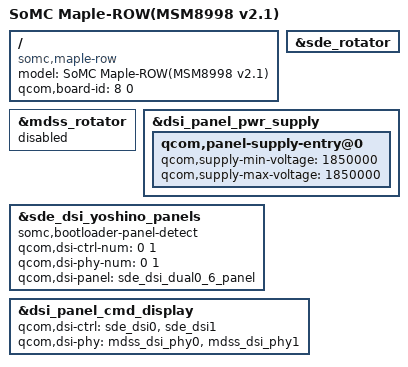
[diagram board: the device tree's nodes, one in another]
/* Copyright (c) 2016, The Linux Foundation. All rights reserved.
 *
 * This program is free software; you can redistribute it and/or modify
 * it under the terms of the GNU General Public License version 2 and
 * only version 2 as published by the Free Software Foundation.
 *
 * This program is distributed in the hope that it will be useful,
 * but WITHOUT ANY WARRANTY; without even the implied warranty of
 * MERCHANTABILITY or FITNESS FOR A PARTICULAR PURPOSE.  See the
 * GNU General Public License for more details.
 */
/*
 * Copyright (C) 2016 Sony Mobile Communications Inc.
 *
 * This program is free software; you can redistribute it and/or modify
 * it under the terms of the GNU General Public License version 2, as
 * published by the Free Software Foundation.
 */


/dts-v1/;

#include "msm8998-v2.1.dtsi"
#include "msm8998-sde.dtsi"
#include "msm8998-sde-display.dtsi"
#include "msm8998-mtp.dtsi"
#include "msm8998-yoshino-common.dtsi"
#include "msm8998-yoshino-common-sde-overlay.dtsi"
#include "msm8998-yoshino-maple_common.dtsi"
#include "dsi-panel-somc-maple-sde.dtsi"

/ {
	model = "SoMC Maple-ROW(MSM8998 v2.1)";
	compatible = "somc,maple-row", "qcom,msm8998";
	qcom,board-id = <8 0>;
};

/* Disable MDSS rotator node to use SDE rotator. */
&mdss_rotator {
	status = "disabled";
};

&sde_rotator {
	status = "ok";
};

&dsi_panel_pwr_supply {
	qcom,panel-supply-entry@0 {
		qcom,supply-min-voltage = <1850000>;
		qcom,supply-max-voltage = <1850000>;
	};
};

&sde_dsi_yoshino_panels {
	/* Only one possible panel on PROD SoMC Maple */
	somc,bootloader-panel-detect;

	/* Dual DSI single panel, clocked from MUX 0 */
	qcom,dsi-ctrl-num = <0 1>;
	qcom,dsi-phy-num = <0 1>;

	qcom,dsi-panel = <&sde_dsi_dual0_6_panel>;
};

&dsi_panel_cmd_display {
	qcom,dsi-ctrl = <&sde_dsi0 &sde_dsi1>;
	qcom,dsi-phy = <&mdss_dsi_phy0 &mdss_dsi_phy1>;
};

